# AES256_356.0 register map
Vendor: Texas Instruments
Peripheral module from a debugger description file (folder MSP432).
Registers are 16-bit, read-write, no defined reset value unless marked. A register's access mark holds for its fields unless they carry their own. Offsets are as the file gives them; lines under a group give offsets from that group; [hi:lo] are bit positions; {n}, {i} and the like mark numbered series; 'fields as' and 'values as' point back to an identical list; <NAME> marks a mode.

## AES256
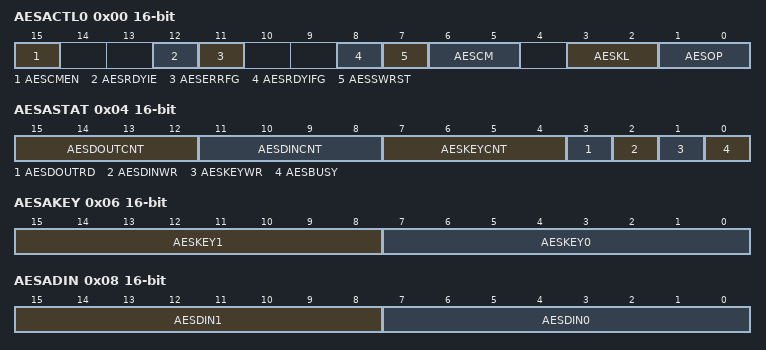
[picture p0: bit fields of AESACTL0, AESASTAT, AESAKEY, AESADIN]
0x00 AESACTL0 — AES Accelerator Control Register 0
  [15] AESCMEN — AES cipher mode enable
    0=DISABLE (No DMA triggers are generated); 1=ENABLE (DMA ciphermode support operation is enabled and the corresponding DMA triggers are generated)
  [12] AESRDYIE — AES ready interrupt enable
    0=DISABLE (Interrupt disabled); 1=ENABLE (Interrupt enabled)
  [11] AESERRFG — AES error flag
    0=No error; 1=Error occurred
  [8] AESRDYIFG — AES ready interrupt flag
    0=No interrupt pending; 1=Interrupt pending
  [7] AESSWRST — AES software reset
    0=No reset; 1=RESET (Reset AES accelerator module)
  [6:5] AESCM — AES cipher mode select
    0=ECB; 1=CBC; 2=OFB; 3=CFB
  [3:2] AESKL — AES key length
    0=128BIT (AES128. The key size is 128 bit); 1=192BIT (AES192. The key size is 192 bit.); 2=256BIT (AES256. The key size is 256 bit)
  [1:0] AESOP — AES operation
    0=Encryption; 1=Decryption. The provided key is the same key used for encryption; 2=Generate first round key required for decryption; 3=Decryption. The provided key is the first round key required for decryption
0x02 AESACTL1 — AES Accelerator Control Register 1
  [7:0] AESBLKCNT — Cipher Block Counter
0x04 AESASTAT access per field — AES Accelerator Status Register
  [15:12] AESDOUTCNT ro — Bytes read via AESADOUT
  [11:8] AESDINCNT ro — Bytes written via AESADIN, AESAXDIN or AESAXIN
  [7:4] AESKEYCNT ro — Bytes written via AESAKEY for AESKLx=00, half-words written via AESAKEY
  [3] AESDOUTRD ro — All 16 bytes read from AESADOUT
    0=Not all bytes read; 1=All bytes read
  [2] AESDINWR rw — All 16 bytes written to AESADIN, AESAXDIN or AESAXIN
    0=Not all bytes written; 1=All bytes written
  [1] AESKEYWR rw — All 16 bytes written to AESAKEY
    0=Not all bytes written; 1=All bytes written
  [0] AESBUSY rw — AES accelerator module busy
    0=IDLE (Not busy); 1=BUSY
0x06 AESAKEY — AES Accelerator Key Register
  [15:8] AESKEY1 — AES key byte n+1 when AESAKEY is written as half-word
  [7:0] AESKEY0 — AES key byte n when AESAKEY is written as half-word
0x08 AESADIN — AES Accelerator Data In Register
  [15:8] AESDIN1 — AES data in byte n+1 when AESADIN is written as half-word
  [7:0] AESDIN0 — AES data in byte n when AESADIN is written as half-word
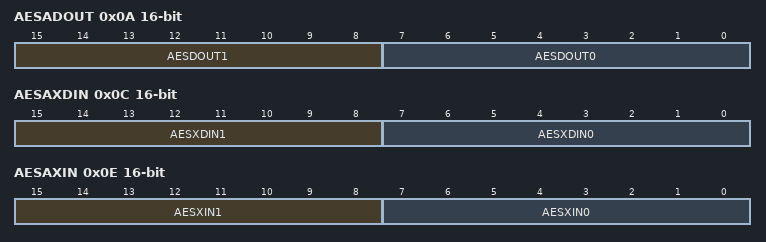
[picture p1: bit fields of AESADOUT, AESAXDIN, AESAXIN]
0x0A AESADOUT — AES Accelerator Data Out Register
  [15:8] AESDOUT1 — AES data out byte n+1 when AESADOUT is read as half-word
  [7:0] AESDOUT0 — AES data out byte n when AESADOUT is read as half-word
0x0C AESAXDIN — AES Accelerator XORed Data In Register
  [15:8] AESXDIN1 — AES data in byte n+1 when AESAXDIN is written as half-word
  [7:0] AESXDIN0 — AES data in byte n when AESAXDIN is written as half-word
0x0E AESAXIN — AES Accelerator XORed Data In Register
  [15:8] AESXIN1 — AES data in byte n+1 when AESAXIN is written as half-word
  [7:0] AESXIN0 — AES data in byte n when AESAXIN is written as half-word
